VERSION ""

NS_ :

BS_:

BU_: XXX ACC_ECU ABS_ECU EPS_ECU

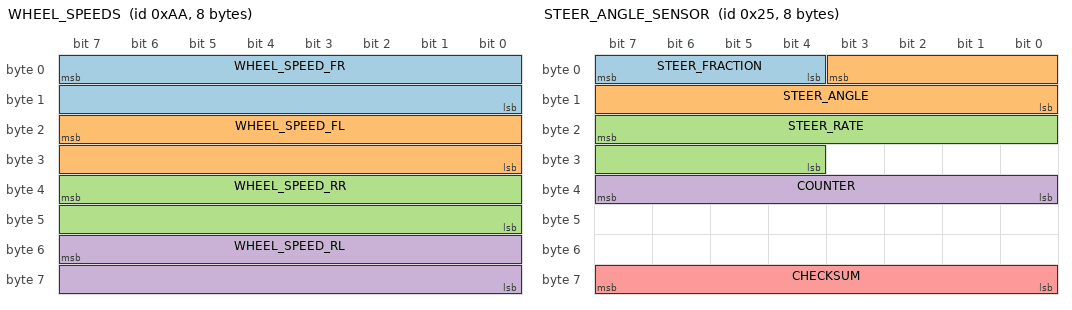
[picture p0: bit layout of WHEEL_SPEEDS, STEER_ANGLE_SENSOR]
BO_ 170 WHEEL_SPEEDS: 8 ABS_ECU
 SG_ WHEEL_SPEED_FR : 7|16@0+ (0.01,-67.67) [0|250] "km/h" XXX
 SG_ WHEEL_SPEED_FL : 23|16@0+ (0.01,-67.67) [0|250] "km/h" XXX
 SG_ WHEEL_SPEED_RR : 39|16@0+ (0.01,-67.67) [0|250] "km/h" XXX
 SG_ WHEEL_SPEED_RL : 55|16@0+ (0.01,-67.67) [0|250] "km/h" XXX

BO_ 37 STEER_ANGLE_SENSOR: 8 EPS_ECU
 SG_ STEER_FRACTION : 7|4@0- (0.1,0) [-0.8|0.7] "deg" XXX
 SG_ STEER_ANGLE : 3|12@0- (1.5,0) [-500|500] "deg" XXX
 SG_ STEER_RATE : 23|12@0- (1,0) [-2048|2047] "deg/s" XXX
 SG_ COUNTER : 39|8@0+ (1,0) [0|255] "" XXX
 SG_ CHECKSUM : 63|8@0+ (1,0) [0|255] "" XXX

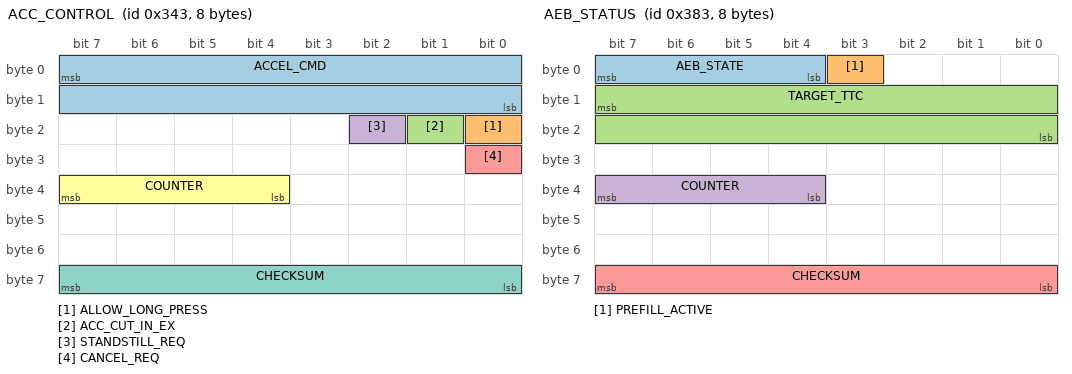
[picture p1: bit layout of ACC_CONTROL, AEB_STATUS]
BO_ 835 ACC_CONTROL: 8 ACC_ECU
 SG_ ACCEL_CMD : 7|16@0- (0.001,0) [-20|20] "m/s2" XXX
 SG_ ALLOW_LONG_PRESS : 16|1@0+ (1,0) [0|1] "" XXX
 SG_ ACC_CUT_IN_EX : 17|1@0+ (1,0) [0|1] "" XXX
 SG_ STANDSTILL_REQ : 18|1@0+ (1,0) [0|1] "" XXX
 SG_ CANCEL_REQ : 24|1@0+ (1,0) [0|1] "" XXX
 SG_ COUNTER : 39|4@0+ (1,0) [0|15] "" XXX
 SG_ CHECKSUM : 63|8@0+ (1,0) [0|255] "" XXX

BO_ 899 AEB_STATUS: 8 ACC_ECU
 SG_ AEB_STATE : 7|4@0+ (1,0) [0|7] "" XXX
 SG_ PREFILL_ACTIVE : 3|1@0+ (1,0) [0|1] "" XXX
 SG_ TARGET_TTC : 15|16@0+ (0.01,0) [0|655.35] "s" XXX
 SG_ COUNTER : 39|4@0+ (1,0) [0|15] "" XXX
 SG_ CHECKSUM : 63|8@0+ (1,0) [0|255] "" XXX

VAL_ 899 AEB_STATE 0 "NORMAL" 1 "WARNING" 2 "EMERGENCY_BRAKING" 3 "FAULT_DEGRADED" ;
